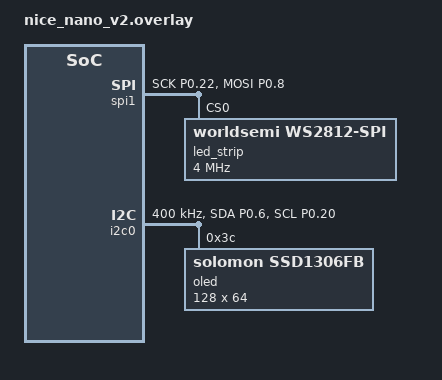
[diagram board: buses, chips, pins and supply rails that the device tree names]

/**
 * Generated by Shield Wizard for ZMK
 * Applies to shield "numpad123_5x5" with board "nice_nano_v2" only
 */

//
// ======== spi1 ========
//

// pin control for spi1
// - SCK on D4
// - MOSI on D0
&pinctrl {
    /* configuration for spi1 device, default state */
    spi1_default: spi1_default {
        group1 {
            psels = <NRF_PSEL(SPIM_SCK, 0, 22)>,
                    <NRF_PSEL(SPIM_MOSI, 0, 8)>;
        };
    };
    /* configuration for spi1 device, sleep state */
    spi1_sleep: spi1_sleep {
        group1 {
            psels = <NRF_PSEL(SPIM_SCK, 0, 22)>,
                    <NRF_PSEL(SPIM_MOSI, 0, 8)>;
            low-power-enable;
        };
    };
};
&spi1 {
  compatible = "nordic,nrf-spim";
  status = "okay";
  pinctrl-0 = <&spi1_default>;
  pinctrl-1 = <&spi1_sleep>;
  pinctrl-names = "default", "sleep";
};

// devices on spi1

#include <dt-bindings/led/led.h>
&spi1 {
    led_strip: ws2812@0 {
        compatible = "worldsemi,ws2812-spi";
        reg = <0>;
        spi-max-frequency = <4000000>;

        chain-length = <25>;
        spi-one-frame = <0x70>;
        spi-zero-frame = <0x40>;
        color-mapping = <LED_COLOR_ID_GREEN
                         LED_COLOR_ID_RED
                         LED_COLOR_ID_BLUE>;
    };
};
/ {
    chosen {
        zmk,underglow = &led_strip;
    };
};

//
// ======== i2c0 ========
//

// pin control for i2c0
// - SDA on D1
// - SCL on D3
&pinctrl {
    /* configuration for i2c0 device, default state */
    i2c0_default: i2c0_default {
        group1 {
            psels = <NRF_PSEL(TWIM_SDA, 0, 6)>,
                    <NRF_PSEL(TWIM_SCL, 0, 20)>;
        };
    };
    /* configuration for i2c0 device, sleep state */
    i2c0_sleep: i2c0_sleep {
        group1 {
            psels = <NRF_PSEL(TWIM_SDA, 0, 6)>,
                    <NRF_PSEL(TWIM_SCL, 0, 20)>;
            low-power-enable;
        };
    };
};
&i2c0 {
  compatible = "nordic,nrf-twim";
  status = "okay";
  pinctrl-0 = <&i2c0_default>;
  pinctrl-1 = <&i2c0_sleep>;
  pinctrl-names = "default", "sleep";
  clock-frequency = <I2C_BITRATE_FAST>;
};

// devices on i2c0

&i2c0 {
    oled: ssd1306@3c {
        compatible = "solomon,ssd1306fb";
        reg = <0x3c>;
        width = <128>;
        height = <64>;

        segment-offset = <0>;
        page-offset = <0>;
        display-offset = <0>;
        multiplex-ratio = <31>;
        prechargep = <0x22>;
        segment-remap;
        com-invdir;
        com-sequential;
        inversion-on;
    };
};
/ {
    chosen {
        zephyr,display = &oled;
    };
};
